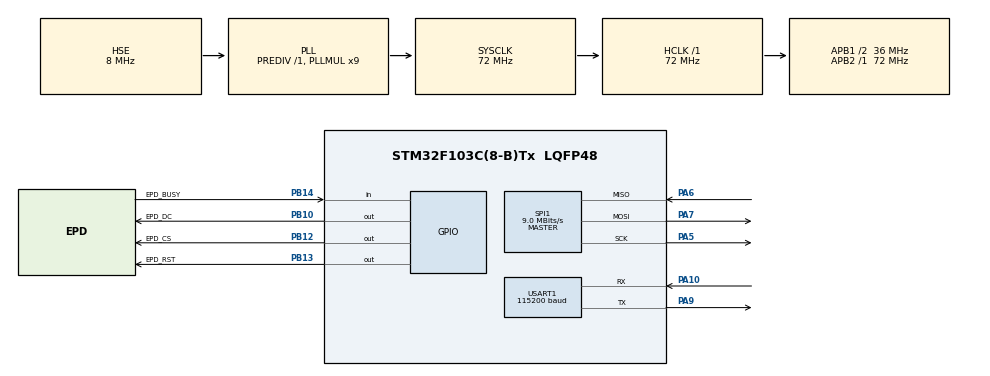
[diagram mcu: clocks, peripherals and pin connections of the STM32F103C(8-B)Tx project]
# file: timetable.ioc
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Mcu.Family=STM32F1
Mcu.Name=STM32F103C(8-B)Tx
Mcu.Package=LQFP48
NVIC.PriorityGroup=NVIC_PRIORITYGROUP_4
PA13.Mode=Serial_Wire
PA13.Signal=SYS_JTMS-SWDIO
PA14.Mode=Serial_Wire
PA14.Signal=SYS_JTCK-SWCLK
PA5.Mode=Full_Duplex_Master
PA5.Signal=SPI1_SCK
PA6.Mode=Full_Duplex_Master
PA6.Signal=SPI1_MISO
PA7.Mode=Full_Duplex_Master
PA7.Signal=SPI1_MOSI
PA9.Mode=Asynchronous
PA9.Signal=USART1_TX
PA10.Mode=Asynchronous
PA10.Signal=USART1_RX
PB10.GPIO_Label=EPD_DC
PB10.GPIO_Speed=GPIO_SPEED_FREQ_HIGH
PB10.Signal=GPIO_Output
PB12.GPIO_Label=EPD_CS
PB12.GPIO_Speed=GPIO_SPEED_FREQ_HIGH
PB12.Signal=GPIO_Output
PB13.GPIO_Label=EPD_RST
PB13.GPIO_Speed=GPIO_SPEED_FREQ_HIGH
PB13.Signal=GPIO_Output
PB14.GPIO_Label=EPD_BUSY
PB14.Signal=GPIO_Input
PD0-OSC_IN.Mode=HSE-External-Oscillator
PD0-OSC_IN.Signal=RCC_OSC_IN
PD1-OSC_OUT.Mode=HSE-External-Oscillator
PD1-OSC_OUT.Signal=RCC_OSC_OUT
ProjectManager.HeapSize=0x200
ProjectManager.StackSize=0x400
ProjectManager.TargetToolchain=CMake
RCC.AHBFreq_Value=72000000
RCC.APB1CLKDivider=RCC_HCLK_DIV2
RCC.APB1Freq_Value=36000000
RCC.APB1TimFreq_Value=72000000
RCC.APB2Freq_Value=72000000
RCC.APB2TimFreq_Value=72000000
RCC.HCLKFreq_Value=72000000
RCC.PLLMUL=RCC_PLL_MUL9
RCC.PLLSourceVirtual=RCC_PLLSOURCE_HSE
RCC.SYSCLKFreq_VALUE=72000000
RCC.SYSCLKSource=RCC_SYSCLKSOURCE_PLLCLK
RCC.USBFreq_Value=72000000
SPI1.BaudRatePrescaler=SPI_BAUDRATEPRESCALER_8
SPI1.CalculateBaudRate=9.0 MBits/s
SPI1.Direction=SPI_DIRECTION_2LINES
SPI1.Mode=SPI_MODE_MASTER
SPI1.VirtualType=VM_MASTER
USART1.BaudRate=115200
USART1.Parity=PARITY_NONE
USART1.StopBits=STOPBITS_1
USART1.VirtualMode=VM_ASYNC
USART1.WordLength=WORDLENGTH_8B
board=custom

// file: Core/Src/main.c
/* USER CODE BEGIN Header */
/**
  ******************************************************************************
  * @file           : main.c
  * @brief          : Main program body
  ******************************************************************************
  * @attention
  *
  * Copyright (c) 2026 STMicroelectronics.
  * All rights reserved.
  *
  * This software is licensed under terms that can be found in the LICENSE file
  * in the root directory of this software component.
  * If no LICENSE file comes with this software, it is provided AS-IS.
  *
  ******************************************************************************
  */
/* USER CODE END Header */
#include "main.h"
#include "spi.h"
#include "gpio.h"
#include "usart.h"

/* USER CODE BEGIN Includes */
#include "epd.h"
#include "log.h"
#include "my_courses.h"
#include "timetable.h"
/* USER CODE END Includes */

void SystemClock_Config(void);

int main(void)
{

  /* MCU Configuration--------------------------------------------------------*/

  /* Reset of all peripherals, Initializes the Flash interface and the Systick. */
  HAL_Init();

  /* Configure the system clock */
  SystemClock_Config();

  /* Initialize all configured peripherals */
  MX_GPIO_Init();
  MX_SPI1_Init();
  MX_USART1_UART_Init();
  /* USER CODE BEGIN 2 */

  LOG_Init();
  LOG("\r\n\r\n### TIMETABLE BOOT ###\r\n");

  /* ── 显示课程表 ──────────────────────────────────────────────────────
   * 流程固定三步：
   *   ① EPD_Init()        初始化屏（复位 + 清显存）
   *   ② MyCourses_Load()  填课表数据（改 Core/Src/my_courses.c）
   *   ③ TT_Show()         绘制 + 刷新 + 进睡眠
   * 墨水屏断电保持画面，所以刷一次就行了，不需要在循环里反复刷。 */
  EPD_Init();
  TT_Clear();
  MyCourses_Load();
  LOG(">>> 开始绘制课程表\r\n");
  TT_Show();
  LOG(">>> 绘制完成，屏已睡眠\r\n");

  /* USER CODE END 2 */

  /* Infinite loop */
  while (1)
  {

    /* USER CODE BEGIN 3 */

    /* 纯显示固件：静态画面，墨水屏断电保持，无需循环刷新。
     * 要接实时更新（切周次/日期变化）在这里加「检测到变化才重绘」，
     * 然后同样调用 TT_Show()。 */
    HAL_Delay(1000);

    /* USER CODE END 3 */
  }
}

void SystemClock_Config(void)
{
  RCC_OscInitTypeDef RCC_OscInitStruct = {0};
  RCC_ClkInitTypeDef RCC_ClkInitStruct = {0};

  /** Initializes the RCC Oscillators according to the specified parameters
  * in the RCC_OscInitTypeDef structure.
  */
  RCC_OscInitStruct.OscillatorType = RCC_OSCILLATORTYPE_HSE;
  RCC_OscInitStruct.HSEState = RCC_HSE_ON;
  RCC_OscInitStruct.HSEPredivValue = RCC_HSE_PREDIV_DIV1;
  RCC_OscInitStruct.HSIState = RCC_HSI_ON;
  RCC_OscInitStruct.PLL.PLLState = RCC_PLL_ON;
  RCC_OscInitStruct.PLL.PLLSource = RCC_PLLSOURCE_HSE;
  RCC_OscInitStruct.PLL.PLLMUL = RCC_PLL_MUL9;
  if (HAL_RCC_OscConfig(&RCC_OscInitStruct) != HAL_OK)
  {
    Error_Handler();
  }

  /** Initializes the CPU, AHB and APB buses clocks
  */
  RCC_ClkInitStruct.ClockType = RCC_CLOCKTYPE_HCLK|RCC_CLOCKTYPE_SYSCLK
                              |RCC_CLOCKTYPE_PCLK1|RCC_CLOCKTYPE_PCLK2;
  RCC_ClkInitStruct.SYSCLKSource = RCC_SYSCLKSOURCE_PLLCLK;
  RCC_ClkInitStruct.AHBCLKDivider = RCC_SYSCLK_DIV1;
  RCC_ClkInitStruct.APB1CLKDivider = RCC_HCLK_DIV2;
  RCC_ClkInitStruct.APB2CLKDivider = RCC_HCLK_DIV1;

  if (HAL_RCC_ClockConfig(&RCC_ClkInitStruct, FLASH_LATENCY_2) != HAL_OK)
  {
    Error_Handler();
  }
}

void Error_Handler(void)
{
  __disable_irq();
  while (1)
  {
  }
}
